# STMP3770 register map
Vendor: Freescale Semiconductor (NXP); Series: STMP37xx; File version: 1.0
CPU: other r0p0, little endian, no MPU, no FPU, 2 interrupt priority bits
Registers are 32-bit, read-write, reset 0x0 unless marked. A register's access mark holds for its fields unless they carry their own. Offsets are from the block's base; [hi:lo] are bit positions.

## UARTAPP — 应用 UART(高速 UART,支持 DMA 收发,区别于调试用 UARTDBG)
Base 0x8006C000
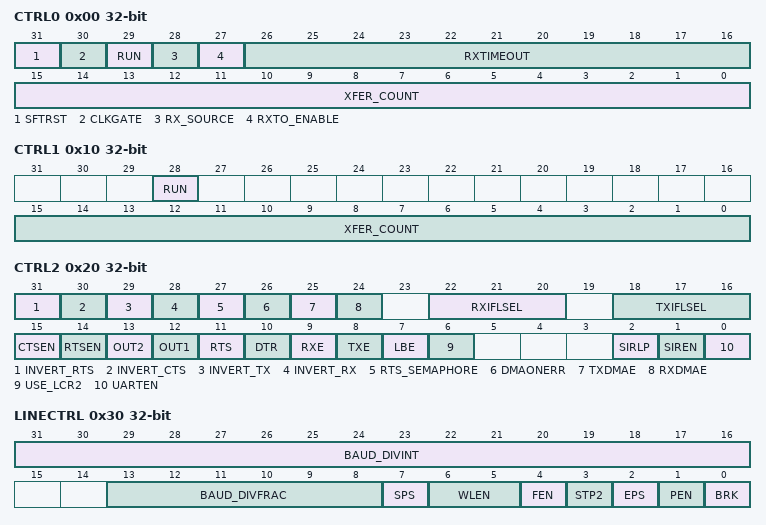
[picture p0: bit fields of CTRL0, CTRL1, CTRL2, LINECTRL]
0x00 CTRL0
  [31] SFTRST — Soft reset. Clear to 0 for normal operation. When set to 1 (default), the entire block is held in its reset state.
  [30] CLKGATE — Clock gate. Clear to 0 for normal operation. Setting to 1 (default) gates all block-level clocks off to minimize AC energy consumption.
  [29] RUN — Tell the UART to execute the RX DMA command. The UART will clear this bit at the end of receive execution.
  [28] RX_SOURCE — Source of Receive Data. If set to 1, the status register will be the source of the DMA; otherwise RX data will be the source.
  [27] RXTO_ENABLE — RXTIMEOUT Enable. 0 = Receive time-out will not affect receive DMA operation. 1 = Receive time-out will cause the receive DMA logic to terminate.
  [26:16] RXTIMEOUT — Receive Time-Out Counter Value [10:0]. Number of 8-bit-time to wait before asserting time-out on the RX input. 7-bit-time is added to the programmed value; default 0x3 (31-bit-time).
  [15:0] XFER_COUNT — Number of bytes to receive [15:0]. Must be a multiple of 4.
0x10 CTRL1
  [28] RUN — Tell the UART to execute the TX DMA command. The UART will clear this bit at the end of transmit execution.
  [15:0] XFER_COUNT — Number of bytes to transmit [15:0].
0x20 CTRL2
  [31] INVERT_RTS — Invert RTS signal. If set to 1, the RTS output is inverted before transmitted.
  [30] INVERT_CTS — Invert CTS signal. If set to 1, the CTS input is inverted before sampled.
  [29] INVERT_TX — Invert TX signal. If set to 1, the TX output is inverted before transmitted.
  [28] INVERT_RX — Invert RX signal. If set to 1, the RX input is inverted before sampled.
  [27] RTS_SEMAPHORE — If set to 1, RTS is deasserted when the semaphore threshold is less than 2.
  [26] DMAONERR — DMA On Error. If set to 1, receive DMA will terminate on error (cmd_end signal may not be asserted when this occurs).
  [25] TXDMAE — Transmit DMA Enable. Data Register can be loaded with up to 4 bytes per write. TXFIFO must be enabled in TXDMA mode.
  [24] RXDMAE — Receive DMA Enable. Data Register can contain up to 4 bytes per read. RXFIFO must be enabled in RXDMA mode.
  [22:20] RXIFLSEL — Receive Interrupt FIFO Level Select [2:0]. Trigger points: 0=NOT_EMPTY (>=1 of 16), 1=ONE_QUARTER (>=4), 2=ONE_HALF (>=8), 3=THREE_QUARTERS (>=12), 4=SEVEN_EIGHTHS (>=14), 5-7=Reserved.
    0=NOT_EMPTY; 1=ONE_QUARTER; 2=ONE_HALF; 3=THREE_QUARTERS; 4=SEVEN_EIGHTHS; 5=INVALID5; 6=INVALID6; 7=INVALID7
  [18:16] TXIFLSEL — Transmit Interrupt FIFO Level Select [2:0]. Trigger points: 0=EMPTY (no entries), 1=ONE_QUARTER (<4), 2=ONE_HALF (<8), 3=THREE_QUARTERS (<12), 4=SEVEN_EIGHTHS (<14), 5-7=Reserved.
    0=EMPTY; 1=ONE_QUARTER; 2=ONE_HALF; 3=THREE_QUARTERS; 4=SEVEN_EIGHTHS; 5=INVALID5; 6=INVALID6; 7=INVALID7
  [15] CTSEN — CTS Hardware Flow Control Enable. If set to 1, CTS hardware flow control is enabled; data is only transmitted when nUARTCTS is asserted.
  [14] RTSEN — RTS Hardware Flow Control Enable. If set to 1, RTS hardware flow control is enabled; data is only requested when there is space in the receive FIFO.
  [13] OUT2 — Complement of the UART Out2 (nUARTOut2) modem status output. Unsupported.
  [12] OUT1 — Complement of the UART Out1 (nUARTOut1) modem status output. Unsupported.
  [11] RTS — Request To Send. Software can manually control nUARTRTS via this bit when RTSEN=0. Complement of nUARTRTS output.
  [10] DTR — Data Transmit Ready. Complement of nUARTDTR modem status output. Unsupported.
  [9] RXE — Receive Enable. If set to 1, the receive section of the UART is enabled. Completes current character before stopping when disabled mid-reception.
  [8] TXE — Transmit Enable. If set to 1, the transmit section of the UART is enabled. Completes current character before stopping when disabled mid-transmission.
  [7] LBE — Loopback Enable. If set to 1, UARTTXD is fed through to UARTRXD. Modem outputs are also fed through to modem inputs.
  [6] USE_LCR2 — If set to 1, the Line Control 2 Register values are used.
  [2] SIRLP — IrDA SIR Low Power Mode. Unsupported.
  [1] SIREN — SIR Enable. Unsupported.
  [0] UARTEN — UART Enable. If set to 1, the UART is enabled. Completes current character before stopping when disabled mid-transmission or reception.
0x30 LINECTRL
  [31:16] BAUD_DIVINT — Baud Rate Integer [15:0]. The integer baud rate divisor.
  [13:8] BAUD_DIVFRAC — Baud Rate Fraction [5:0]. The fractional baud rate divisor.
  [7] SPS — Stick Parity Select. When bits 1,2,7 are set, parity is transmitted/checked as 0. When bits 1 and 7 set, bit 2 clear, parity is transmitted/checked as 1. Cleared = stick parity disabled.
  [6:5] WLEN — Word Length [1:0]. 11=8 bits, 10=7 bits, 01=6 bits, 00=5 bits.
  [4] FEN — Enable FIFOs. 1 = FIFO mode enabled. 0 = FIFOs disabled (character mode, 1-byte-deep holding registers).
  [3] STP2 — Two Stop Bits Select. If set to 1, two stop bits are transmitted at end of frame. Receive logic does not check for two stop bits.
  [2] EPS — Even Parity Select. 1 = even parity generation and checking. 0 = odd parity. No effect when PEN=0.
  [1] PEN — Parity Enable. 1 = parity checking and generation enabled. 0 = parity disabled, no parity bit added.
  [0] BRK — Send Break. If set to 1, a low-level is continually output on UARTTXD after completing current character. Must be set for at least two complete frames. Normal use: cleared to 0.
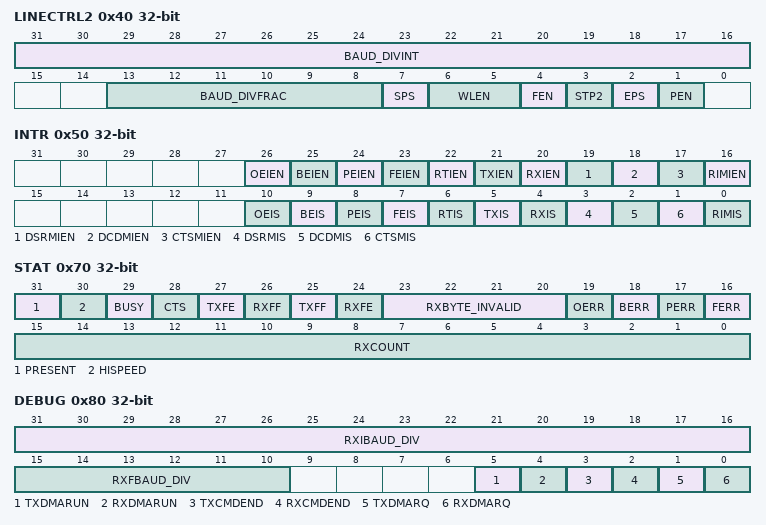
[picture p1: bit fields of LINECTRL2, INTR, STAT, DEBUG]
0x40 LINECTRL2
  [31:16] BAUD_DIVINT — Baud Rate Integer [15:0]. The integer baud rate divisor.
  [13:8] BAUD_DIVFRAC — Baud Rate Fraction [5:0]. The fractional baud rate divisor.
  [7] SPS — Stick Parity Select. Same behavior as HW_UARTAPP_LINECTRL.SPS.
  [6:5] WLEN — Word Length [1:0]. 00=5 bits, 01=6 bits, 10=7 bits, 11=8 bits.
  [4] FEN — Enable FIFOs. 1 = FIFO mode enabled. 0 = FIFOs disabled (character mode).
  [3] STP2 — Two Stop Bits Select. Same behavior as HW_UARTAPP_LINECTRL.STP2.
  [2] EPS — Even Parity Select. 1 = even parity. 0 = odd parity. No effect when PEN=0.
  [1] PEN — Parity Enable. 1 = parity checking/generation enabled. 0 = disabled.
0x50 INTR
  [26] OEIEN — Overrun Error Interrupt Enable.
  [25] BEIEN — Break Error Interrupt Enable.
  [24] PEIEN — Parity Error Interrupt Enable.
  [23] FEIEN — Framing Error Interrupt Enable.
  [22] RTIEN — Receive Time-Out Interrupt Enable.
  [21] TXIEN — Transmit Interrupt Enable.
  [20] RXIEN — Receive Interrupt Enable.
  [19] DSRMIEN — nUARTDSR Modem Interrupt Enable. Unsupported.
  [18] DCDMIEN — nUARTDCD Modem Interrupt Enable. Unsupported.
  [17] CTSMIEN — nUARTCTS Modem Interrupt Enable.
  [16] RIMIEN — nUARTRI Modem Interrupt Enable. Unsupported.
  [10] OEIS — Overrun Error Interrupt Status. Clear by writing bit-clear address with bit set to 1.
  [9] BEIS — Break Error Interrupt Status. Clear by writing bit-clear address with bit set to 1.
  [8] PEIS — Parity Error Interrupt Status. Clear by writing bit-clear address with bit set to 1.
  [7] FEIS — Framing Error Interrupt Status. Clear by writing bit-clear address with bit set to 1.
  [6] RTIS — Receive Time-Out Interrupt Status. Clear by writing bit-clear address with bit set to 1.
  [5] TXIS — Transmit Interrupt Status. Clear by writing bit-clear address with bit set to 1.
  [4] RXIS — Receive Interrupt Status. Clear by writing bit-clear address with bit set to 1.
  [3] DSRMIS — nUARTDSR Modem Interrupt Status. Unsupported.
  [2] DCDMIS — nUARTDCD Modem Interrupt Status. Unsupported.
  [1] CTSMIS — nUARTCTS Modem Interrupt Status. Clear by writing bit-clear address with bit set to 1.
  [0] RIMIS — nUARTRI Modem Interrupt Status. Unsupported.
0x60 DATA
  [31:0] DATA — Receive/Transmit data [31:0]. In DMA mode, up to 4 characters accessed at a time. In PIO mode, only one character at a time.
0x70 STAT
  [31] PRESENT — Indicates UARTAPP is present when reads back 1. 0=UARTAPP not present, 1=UARTAPP present.
    0=UNAVAILABLE; 1=AVAILABLE
  [30] HISPEED — Indicates high-speed function is present when reads back 1. 0=HISPEED not present, 1=HISPEED present.
    0=UNAVAILABLE; 1=AVAILABLE
  [29] BUSY — UART Busy.
  [28] CTS — Clear To Send.
  [27] TXFE — Transmit FIFO Empty. With FIFO disabled: set when transmit holding register is empty. With FIFO enabled: set when transmit FIFO is empty.
  [26] RXFF — Receive FIFO Full.
  [25] TXFF — Transmit FIFO Full.
  [24] RXFE — Receive FIFO Empty.
  [23:20] RXBYTE_INVALID — Invalid state of last read of Receive Data [3:0]. Each bit corresponds to one byte of RX data. 1=invalid.
  [19] OERR — Overrun Error. Set if data received and FIFO already full. Cleared by any write to the Status Register.
  [18] BERR — Break Error. For PIO mode: last character read from data register. For DMA mode: set if any received character had a Break Error. Clear by writing 0.
  [17] PERR — Parity Error. For PIO mode: last character read. For DMA mode: set if any received character had a Parity Error. Clear by writing 0.
  [16] FERR — Framing Error. For PIO mode: last character read. For DMA mode: set if any received character had a Framing Error. Clear by writing 0.
  [15:0] RXCOUNT — Number of bytes received during a receive DMA command [15:0].
0x80 DEBUG ro
  [31:16] RXIBAUD_DIV — 接收波特率分频小数部分（调试用）。
  [15:10] RXFBAUD_DIV — 接收波特率分频整数部分（调试用）。
  [5] TXDMARUN — DMA Command Run Status. Reflects state of toggle signal for TXDMARUN.
  [4] RXDMARUN — DMA Command Run Status. Reflects state of toggle signal for RXDMARUN.
  [3] TXCMDEND — DMA Command End Status. Reflects state of toggle signal for UART_TXCMDEND.
  [2] RXCMDEND — DMA Command End Status. Reflects state of toggle signal for UART_RXCMDEND.
  [1] TXDMARQ — DMA Request Status. Reflects state of toggle signal for UART_TXDMAREQ. TX burst request not supported.
  [0] RXDMARQ — DMA Request Status. Reflects state of toggle signal for UART_RXDMAREQ. RX burst request not supported.
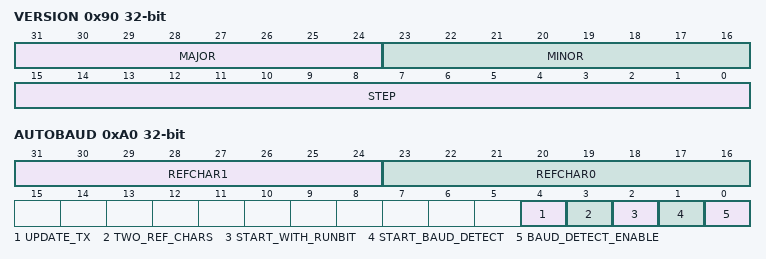
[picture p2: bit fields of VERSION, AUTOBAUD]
0x90 VERSION ro
  [31:24] MAJOR — Fixed read-only value reflecting the MAJOR field of RTL version [7:0].
  [23:16] MINOR — Fixed read-only value reflecting the MINOR field of RTL version [7:0].
  [15:0] STEP — Fixed read-only value reflecting the stepping of RTL version [15:0].
0xA0 AUTOBAUD
  [31:24] REFCHAR1 — 波特率检测参考字符1，用于双字符模式。
  [23:16] REFCHAR0 — 波特率检测参考字符0，用于测量接收波特率。
  [4] UPDATE_TX — 将检测到的波特率同时更新到发送通道。
  [3] TWO_REF_CHARS — 使用两个参考字符进行波特率检测。
  [2] START_WITH_RUNBIT — 检测到RUN位时启动波特率检测。
  [1] START_BAUD_DETECT — 启动波特率检测，写1开始自动波特率测量。
  [0] BAUD_DETECT_ENABLE — 波特率检测使能，置位时UART自动检测接收数据的波特率。
